# USB_USB2SS_PORT_31000420h register map
Vendor: Texas Instruments
Peripheral module from a debugger description file (folder am62D).
Registers are 32-bit, access not given, reset 0x0 unless marked. A register's access mark holds for its fields unless they carry their own. Offsets are as the file gives them; lines under a group give offsets from that group; [hi:lo] are bit positions; {n}, {i} and the like mark numbered series; 'fields as' and 'values as' point back to an identical list; <NAME> marks a mode.

## USB2SS_PORT
0x00 USB2SS_PORT_XHCI_PORT_20 reset not defined
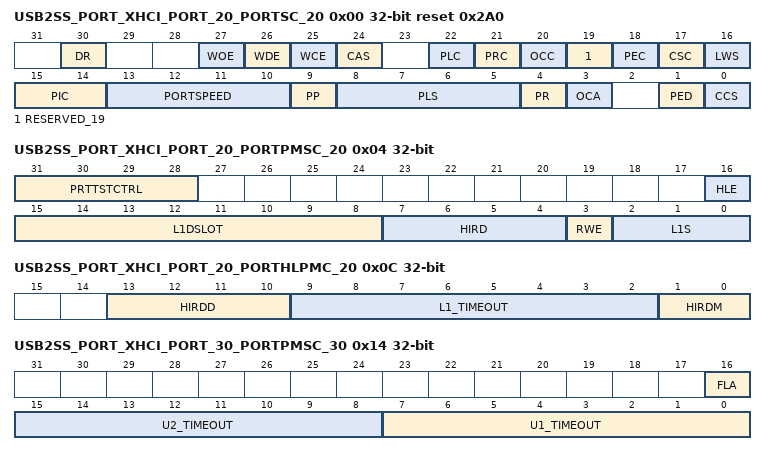
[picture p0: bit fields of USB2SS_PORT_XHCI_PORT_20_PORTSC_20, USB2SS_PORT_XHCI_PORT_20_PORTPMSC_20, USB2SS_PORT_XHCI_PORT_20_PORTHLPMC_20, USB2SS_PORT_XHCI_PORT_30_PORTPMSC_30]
0x00 USB2SS_PORT_XHCI_PORT_20_PORTSC_20 reset 0x2A0 — Port Status and Control Register Bit DefinitionsThe PORTSC Register Access fails (Timeout) if the UTMI/ULPI clock is not running or one of the following bits is asserted. - PR - ORC
  [30] DR ro — Reset ValueFor a description of this standard USB register field, see the eXtensible Host Controller Interface for Universal Serial Bus [USB] Specification 3.0. Reset Source: rst_mod_g_rst_n
  [27] WOE rw — WOEFor a description of this standard USB register field, see the eXtensible Host Controller Interface for Universal Serial Bus [USB] Specification 3.0. Reset Source: rst_mod_g_rst_n
  [26] WDE rw — WDEFor a description of this standard USB register field, see the eXtensible Host Controller Interface for Universal Serial Bus [USB] Specification 3.0. Reset Source: rst_mod_g_rst_n
  [25] WCE rw — WCEFor a description of this standard USB register field, see the eXtensible Host Controller Interface for Universal Serial Bus [USB] Specification 3.0. Reset Source: rst_mod_g_rst_n
  [24] CAS ro — Cold Attach StatusFor a description of this standard USB register field, see the eXtensible Host Controller Interface for Universal Serial Bus [USB] Specification 3.0. Reset Source: rst_mod_g_rst_n
  [22] PLC — PLCFor a description of this standard USB register field, see the eXtensible Host Controller Interface for Universal Serial Bus [USB] Specification 3.0. Reset Source: rst_mod_g_rst_n (access R/W1TC)
  [21] PRC — PRCFor a description of this standard USB register field, see the eXtensible Host Controller Interface for Universal Serial Bus [USB] Specification 3.0.Programming this field with random data will cause side effect. Bit Bash register testing is not recommended. Reset Source: rst_mod_g_rst_n (access R/W1TC)
  [20] OCC — OCCFor a description of this standard USB register field, see the eXtensible Host Controller Interface for Universal Serial Bus [USB] Specification 3.0. Reset Source: rst_mod_g_rst_n (access R/W1TC)
  [19] RESERVED_19 — WRC For a description of this standard USB register field, see the eXtensible Host Controller Interface for Universal Serial Bus [USB] Specification 3.0. (access R/W1TC)
  [18] PEC — PECFor a description of this standard USB register field, see the eXtensible Host Controller Interface for Universal Serial Bus [USB] Specification 3.0. Reset Source: rst_mod_g_rst_n (access R/W1TC)
  [17] CSC — CSCFor a description of this standard USB register field, see the eXtensible Host Controller Interface for Universal Serial Bus [USB] Specification 3.0. Reset Source: rst_mod_g_rst_n (access R/W1TC)
  [16] LWS rw — LWSFor a description of this standard USB register field, see the eXtensible Host Controller Interface for Universal Serial Bus [USB] Specification 3.0. Reset Source: rst_mod_g_rst_n
  [15:14] PIC rw — PICFor a description of this standard USB register field, see the eXtensible Host Controller Interface for Universal Serial Bus [USB] Specification 3.0. Reset Source: rst_mod_g_rst_n
  [13:10] PORTSPEED ro — PORTSPEEDFor a description of this standard USB register field, see the eXtensible Host Controller Interface for Universal Serial Bus [USB] Specification 3.0. Reset Source: rst_mod_g_rst_n
  [9] PP rw — PPFor a description of this standard USB register field, see the eXtensible Host Controller Interface for Universal Serial Bus [USB] Specification 3.0. Reset Source: rst_mod_g_rst_n
  [8:5] PLS rw — PLSFor a description of this standard USB register field, see the eXtensible Host Controller Interface for Universal Serial Bus [USB] Specification 3.0. Reset Source: rst_mod_g_rst_n
  [4] PR — PRset_register_field_attribute DWC_usb3_map/DWC_usb3_block_Host_Cntrl_Port_Reg_Set/PORTSC_20_REGS/PORTSC_20/PR VolatileMemory 1 Programming this field with random data will cause side effect. Bit Bash register testing is not recommended. Reset Source: rst_mod_g_rst_n (access R/W1TS)
  [3] OCA ro — OCAFor a description of this standard USB register field, see the eXtensible Host Controller Interface for Universal Serial Bus [USB] Specification 3.0. Reset Source: rst_mod_g_rst_n
  [1] PED — PEDFor a description of this standard USB register field, see the eXtensible Host Controller Interface for Universal Serial Bus [USB] Specification 3.0. Reset Source: rst_mod_g_rst_n (access R/W1TC)
  [0] CCS ro — CCSFor a description of this standard USB register field, see the eXtensible Host Controller Interface for Universal Serial Bus [USB] Specification 3.0. Reset Source: rst_mod_g_rst_n
0x04 USB2SS_PORT_XHCI_PORT_20_PORTPMSC_20 access per field — USB3 Port Power Management Status and Control Register Bit DefinitionsThis register is in the Aux Power well. It is only reset by platform hardware during a cold reset or in response to a Host Controller Reset (HCRST). Programming this field with random data will cause side effect i.e. Register Access will fail (Timeout) if the pipe clock is not running or reset is asserted . Bit Bash register testing is not recommended.
  [31:28] PRTTSTCTRL rw — Port Test ControlFor a description of this standard USB register field, see the eXtensible Host Controller Interface for Universal Serial Bus [USB] Specification 3.0. Reset Source: rst_mod_g_rst_n
  [16] HLE rw — Port Test ControlFor a description of this standard USB register field, see the eXtensible Host Controller Interface for Universal Serial Bus [USB] Specification 3.0. Reset Source: rst_mod_g_rst_n
  [15:8] L1DSLOT rw — L1DSLOTFor a description of this standard USB register field, see the eXtensible Host Controller Interface for Universal Serial Bus [USB] Specification 3.0. Reset Source: rst_mod_g_rst_n
  [7:4] HIRD rw — Host Initiated Resume Duration [HIRD] - RW. Default = '0'. System software sets this field to indicate to the recipient device how long the xHC will drive resume if it [the xHC] initiates an exit from L1. The HIRD value is encoded as follows: Value Description 0h 50us. [default] 1h 125us. 2h 200us. Fh 1.175 ms. The value of 0000b is interpreted as 50us. Each incrementing value up adds 75us. to the previous value. For example, 0001b is 125us, 0010b is 200us and so on. Based on this rule, the maximum value resume drive time is at encoding value 1111b which represents 1.2ms. Note that the HIRD field is used by both software and hardware controlled LPM. Refer to section 4.23.5.1.1 for more information on HIRD use. Refer to Section 4.1 of the USB2 LPM spec for more information on the use of the HIRD field. Reset Source: rst_mod_g_rst_n
  [3] RWE rw — RWE Port Test ControlFor a description of this standard USB register field, see the eXtensible Host Controller Interface for Universal Serial Bus [USB] Specification 3.0. Reset Source: rst_mod_g_rst_n
  [2:0] L1S ro — L1 Status [L1S] - RO. Default = 0. This field is used by software to determine whether an L1-based suspend request [LMP transaction] was successful, specifically: Value Meaning 0 Invalid - This field is ignored by software. - 1 Success - Port successfully transitioned to L1 [ACK] - 2 Not Yet - Device is unable to enter L1 at this time [NYET] - 3 Not Supported -Device does not support L1 transitions [STALL] - 4 Timeout/Error -Device failed to respond to the LPM Transaction or an error occurred - 5-7 Reserved The value of this field is only valid when the port resides in the L0 or L1 state [PLS = '0' or '2']. Refer to section 4.23.5.1.1 for more information. Reset Source: rst_mod_g_rst_n
0x08 USB2SS_PORT_XHCI_PORT_20_PORTLI_20 reset not defined — Port Link Info RegisterProgramming this field with random data will cause side effect i.e. Register Access will fail (Timeout) if the pipe clock is not running or reset is asserted . Bit Bash register testing is not recommended.
0x0C USB2SS_PORT_XHCI_PORT_20_PORTHLPMC_20 access per field — USB2 Port Hardware LPM Control Register Bit DefinitionsFor a description of this standard USB register field, see the eXtensible Host Controller Interface for Universal Serial Bus (USB) Specification 3.0.
  [13:10] HIRDD rw — PORTHLPMC_20 HIRDD Reset Source: rst_mod_g_rst_n
  [9:2] L1_TIMEOUT rw — PORTHLPMC_20 L1_TIMEOUT.For a description of this standard USB register field, see the eXtensible Host Controller Interface for Universal Serial Bus [USB] Specification 3.0. Reset Source: rst_mod_g_rst_n
  [1:0] HIRDM rw — Host Initiated Resume Duration Mode [HIRDM] - RWS. Default = 0h. Indicates which HIRD value must be used. The following are permissible values: Value Description 0 Initiate L1 using HIRD only on timeout. [default] 1 Initiate L1 using HIRDD on timeout. If rejected by device, initiate L1 using HIRD. 3-2 Reserved. Reset Source: rst_mod_g_rst_n
0x10 USB2SS_PORT_XHCI_PORT_30 reset not defined
0x14 USB2SS_PORT_XHCI_PORT_30_PORTPMSC_30 rw — USB3 Port Power Management Status and Control Register Bit DefinitionsThis register is in the Aux Power well. It is only reset by platform hardware during a cold reset or in response to a Host Controller Reset (HCRST). Programming this field with random data will cause side effect i.e. Register Access will fail (Timeout) if the pipe clock is not running or reset is asserted . Bit Bash register testing is not recommended.
  [16] FLA — FLAFor a description of this standard USB register field, see the eXtensible Host Controller Interface for Universal Serial Bus [USB] Specification 3.0. Reset Source: rst_mod_g_rst_n
  [15:8] U2_TIMEOUT — U2_TIMEOUTFor a description of this standard USB register field, see the eXtensible Host Controller Interface for Universal Serial Bus [USB] Specification 3.0. Reset Source: rst_mod_g_rst_n
  [7:0] U1_TIMEOUT — U1_TIMEOUTFor a description of this standard USB register field, see the eXtensible Host Controller Interface for Universal Serial Bus [USB] Specification 3.0. Reset Source: rst_mod_g_rst_n
0x18 USB2SS_PORT_XHCI_PORT_30_PORTLI_30 ro — Port Link Info RegisterProgramming this field with random data will cause side effect i.e. Register Access will fail (Timeout) if the pipe clock is not running or reset is asserted . Bit Bash register testing is not recommended.
  [15:0] LINK_ERROR_COUNT — LINK_ERROR_COUNTFor a description of this standard USB register field, see the eXtensible Host Controller Interface for Universal Serial Bus [USB] Specification 3.0. Reset Source: rst_mod_g_rst_n
0x1C USB2SS_PORT_XHCI_PORT_30_PORTHLPMC_30 ro — USB2 Port Hardware LPM Control Register Bit DefinitionsFor a description of this standard USB register field, see the eXtensible Host Controller Interface for Universal Serial Bus (USB) Specification 3.0.
